# XHSC_HC32L021 register map
Vendor: XHSC Co.Ltd; Series: ARMCM0+; File version: 1.0
CPU: CM0+ r0p1, little endian, no MPU, no FPU, 2 interrupt priority bits
Registers are 32-bit, read-write, reset 0x0 unless marked. A register's access mark holds for its fields unless they carry their own. Offsets are from the block's base; [hi:lo] are bit positions; 'fields as' and 'values as' point back to an identical list.

## IWDT
Base 0x40001000
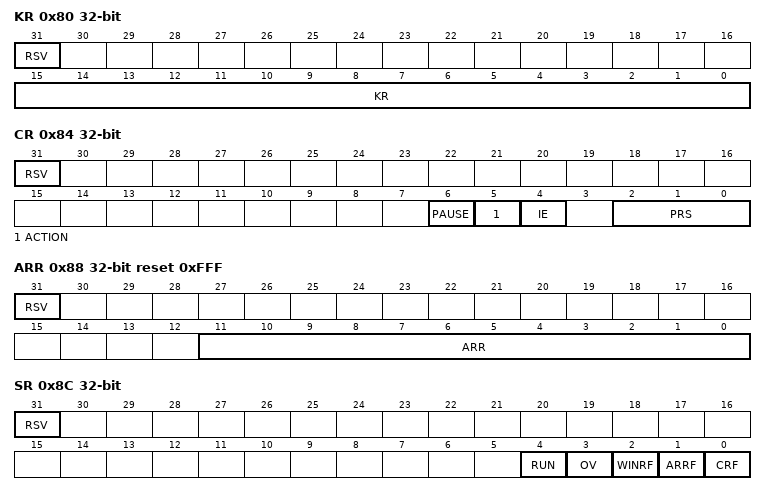
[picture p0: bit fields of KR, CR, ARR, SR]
0x80 KR wo (reset mask 0xFFFF)
  [31] RSV, [15:0] KR
0x84 CR (reset mask 0x77)
  [31] RSV, [6] PAUSE, [5] ACTION, [4] IE, [2:0] PRS
0x88 ARR reset 0xFFF (reset mask 0xFFF)
  [31] RSV, [11:0] ARR
0x8C SR (reset mask 0x1F)
  [31] RSV ro, [4] RUN ro, [3] OV ro, [2] WINRF ro, [1] ARRF ro, [0] CRF ro
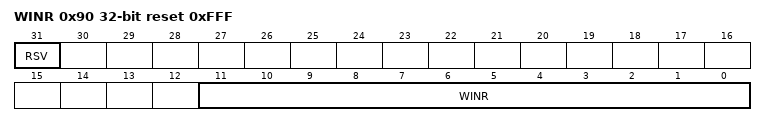
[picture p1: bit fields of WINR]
0x90 WINR reset 0xFFF (reset mask 0xFFF)
  [31] RSV, [11:0] WINR

## LPUART0 — desc LPUART
Base 0x40000000
Same registers: LPUART1 0x40008000
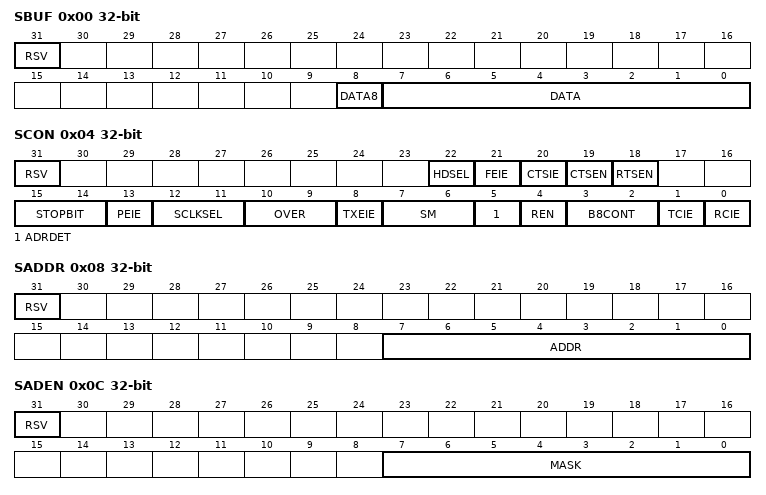
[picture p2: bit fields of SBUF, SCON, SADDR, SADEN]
0x00 SBUF (reset mask 0x1FF)
  [31] RSV, [8] DATA8, [7:0] DATA
0x04 SCON (reset mask 0x7FFFFF)
  [31] RSV, [22] HDSEL, [21] FEIE, [20] CTSIE, [19] CTSEN, [18] RTSEN, [15:14] STOPBIT, [13] PEIE, [12:11] SCLKSEL, [10:9] OVER, [8] TXEIE, [7:6] SM, [5] ADRDET, [4] REN, [3:2] B8CONT, [1] TCIE, [0] RCIE
0x08 SADDR (reset mask 0xFF)
  [31] RSV, [7:0] ADDR
0x0C SADEN (reset mask 0xFF)
  [31] RSV, [7:0] MASK
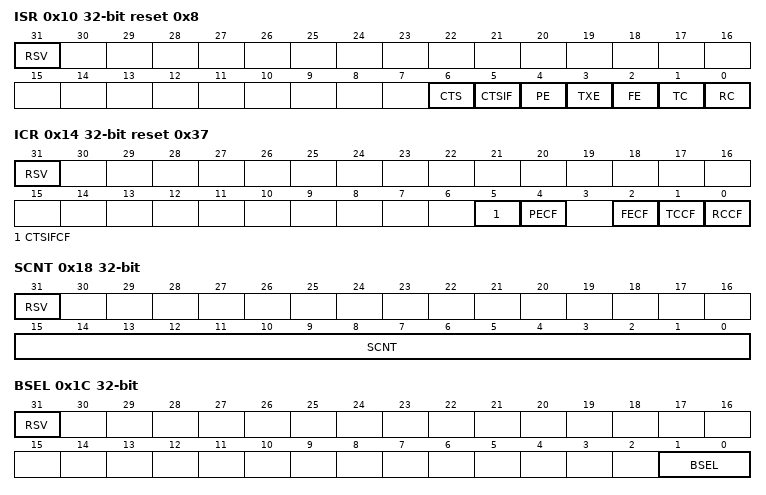
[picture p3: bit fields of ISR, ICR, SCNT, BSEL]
0x10 ISR ro reset 0x8 (reset mask 0x7F)
  [31] RSV rw, [6] CTS, [5] CTSIF, [4] PE, [3] TXE, [2] FE, [1] TC, [0] RC
0x14 ICR wo reset 0x37 (reset mask 0x37)
  [31] RSV rw, [5] CTSIFCF, [4] PECF, [2] FECF, [1] TCCF, [0] RCCF
0x18 SCNT (reset mask 0xFFFF)
  [31] RSV, [15:0] SCNT
0x1C BSEL (reset mask 0x3)
  [31] RSV, [1:0] BSEL
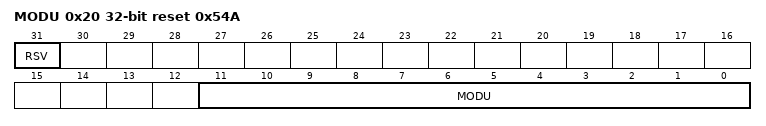
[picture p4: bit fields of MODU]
0x20 MODU reset 0x54A (reset mask 0xFFF)
  [31] RSV, [11:0] MODU

## LVD
Base 0x40002C00
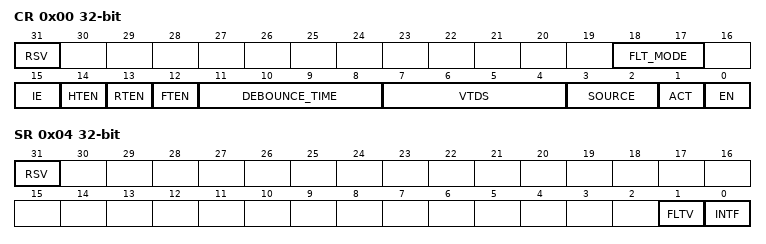
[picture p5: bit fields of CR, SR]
0x00 CR (reset mask 0x6FFFF)
  [31] RSV, [18:17] FLT_MODE, [15] IE, [14] HTEN, [13] RTEN, [12] FTEN, [11:8] DEBOUNCE_TIME, [7:4] VTDS, [3:2] SOURCE, [1] ACT, [0] EN
0x04 SR (reset mask 0x3)
  [31] RSV, [1] FLTV ro, [0] INTF

## RTC
Base 0x40001400
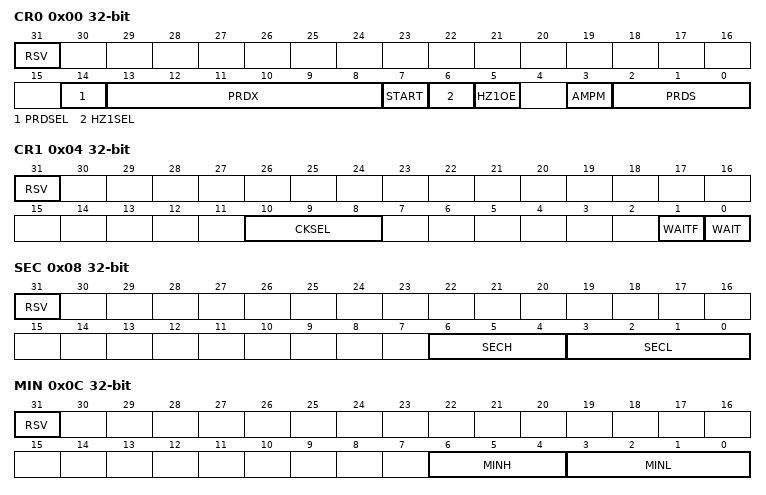
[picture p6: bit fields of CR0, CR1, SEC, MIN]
0x00 CR0 (reset mask 0xFFEF)
  [31] RSV, [14] PRDSEL, [13:8] PRDX, [7] START, [6] HZ1SEL, [5] HZ1OE, [3] AMPM, [2:0] PRDS
0x04 CR1 (reset mask 0x303)
  [31] RSV, [10:8] CKSEL, [1] WAITF, [0] WAIT
0x08 SEC (reset mask 0x7F)
  [31] RSV, [6:4] SECH, [3:0] SECL
0x0C MIN (reset mask 0x7F)
  [31] RSV, [6:4] MINH, [3:0] MINL
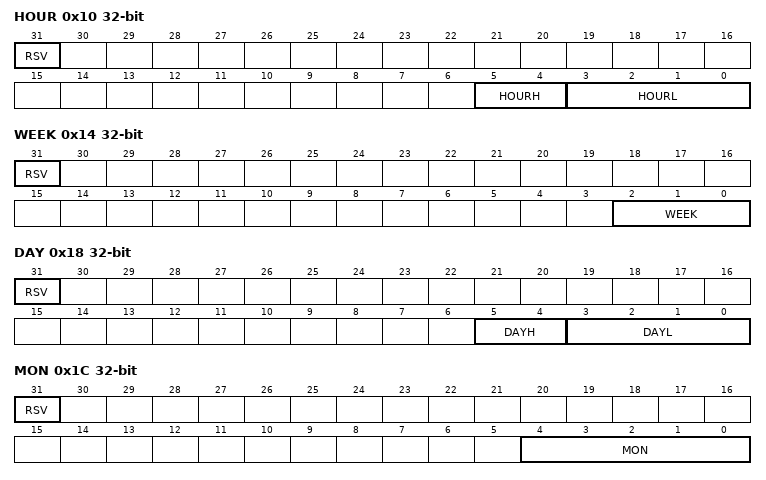
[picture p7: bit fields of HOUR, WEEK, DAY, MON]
0x10 HOUR (reset mask 0x3F)
  [31] RSV, [5:4] HOURH, [3:0] HOURL
0x14 WEEK (reset mask 0x7)
  [31] RSV, [2:0] WEEK
0x18 DAY (reset mask 0x3F)
  [31] RSV, [5:4] DAYH, [3:0] DAYL
0x1C MON (reset mask 0x1F)
  [31] RSV, [4:0] MON
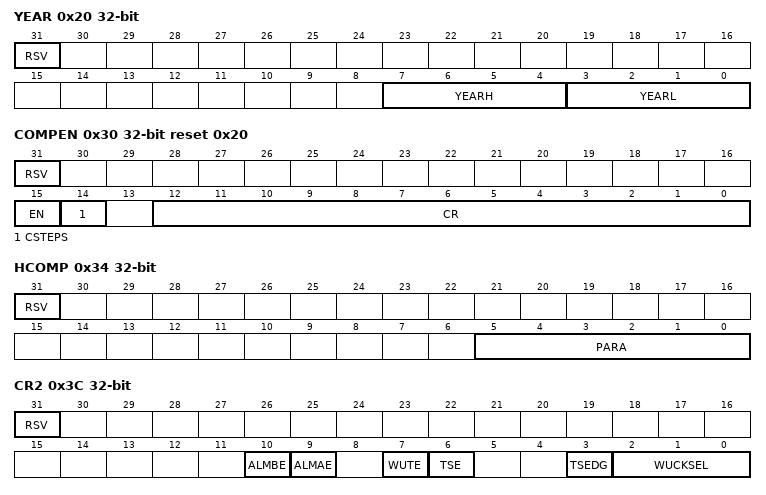
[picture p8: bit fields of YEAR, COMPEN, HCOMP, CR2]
0x20 YEAR (reset mask 0xFF)
  [31] RSV, [7:4] YEARH, [3:0] YEARL
0x30 COMPEN reset 0x20 (reset mask 0x18FF)
  [31] RSV, [15] EN, [14] CSTEPS, [12:0] CR
0x34 HCOMP (reset mask 0x3F)
  [31] RSV, [5:0] PARA
0x3C CR2 (reset mask 0x6FF)
  [31] RSV, [10] ALMBE, [9] ALMAE, [7] WUTE, [6] TSE, [3] TSEDG, [2:0] WUCKSEL
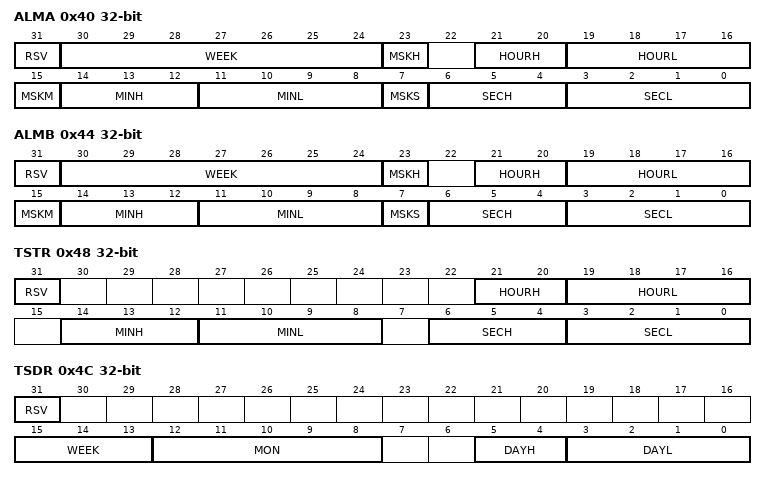
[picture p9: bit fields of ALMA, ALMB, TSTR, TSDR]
0x40 ALMA (reset mask 0x7FBFFFFF)
  [31] RSV, [30:24] WEEK, [23] MSKH, [21:20] HOURH, [19:16] HOURL, [15] MSKM, [14:12] MINH, [11:8] MINL, [7] MSKS, [6:4] SECH, [3:0] SECL
0x44 ALMB (reset mask 0x7FBFFFFF)
  fields as ALMA
0x48 TSTR ro (reset mask 0x3F7F7F)
  [31] RSV, [21:20] HOURH, [19:16] HOURL, [14:12] MINH, [11:8] MINL, [6:4] SECH, [3:0] SECL
0x4C TSDR ro (reset mask 0xFF3F)
  [31] RSV, [15:13] WEEK, [12:8] MON, [5:4] DAYH, [3:0] DAYL
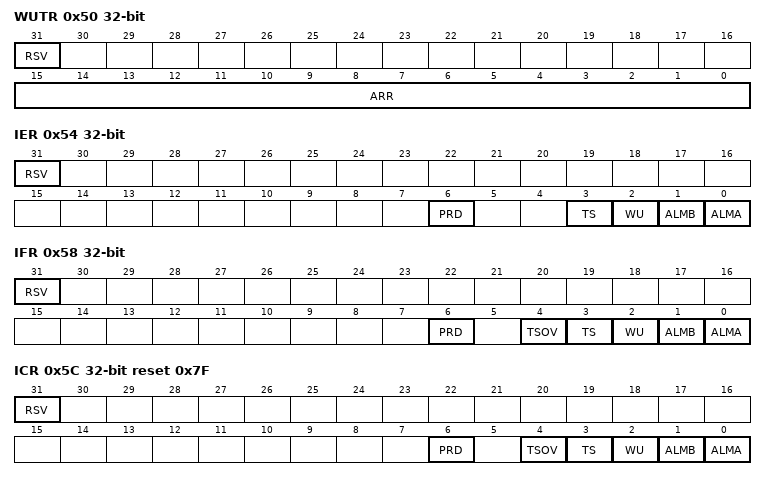
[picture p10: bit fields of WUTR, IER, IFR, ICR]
0x50 WUTR (reset mask 0xFFFF)
  [31] RSV, [15:0] ARR
0x54 IER (reset mask 0x5F)
  [31] RSV, [6] PRD, [3] TS, [2] WU, [1] ALMB, [0] ALMA
0x58 IFR ro (reset mask 0x5F)
  [31] RSV, [6] PRD, [4] TSOV, [3] TS, [2] WU, [1] ALMB, [0] ALMA
0x5C ICR reset 0x7F (reset mask 0x5F)
  [31] RSV, [6] PRD, [4] TSOV, [3] TS, [2] WU, [1] ALMB, [0] ALMA
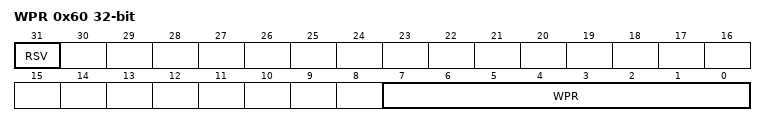
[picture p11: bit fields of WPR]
0x60 WPR (reset mask 0xFF)
  [31] RSV, [7:0] WPR

## SPI
Base 0x40000800
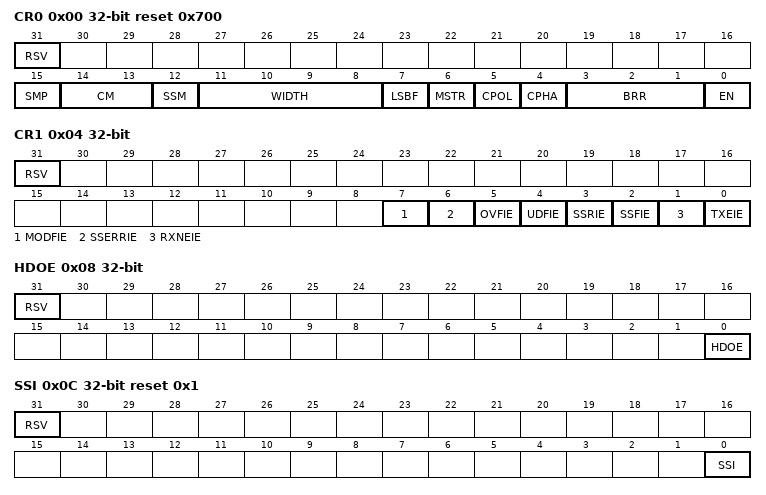
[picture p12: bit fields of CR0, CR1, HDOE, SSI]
0x00 CR0 reset 0x700 (reset mask 0xFFFF)
  [31] RSV, [15] SMP, [14:13] CM, [12] SSM, [11:8] WIDTH, [7] LSBF, [6] MSTR, [5] CPOL, [4] CPHA, [3:1] BRR, [0] EN
0x04 CR1 (reset mask 0xFF)
  [31] RSV, [7] MODFIE, [6] SSERRIE, [5] OVFIE, [4] UDFIE, [3] SSRIE, [2] SSFIE, [1] RXNEIE, [0] TXEIE
0x08 HDOE (reset mask 0x1)
  [31] RSV, [0] HDOE
0x0C SSI reset 0x1 (reset mask 0x1)
  [31] RSV, [0] SSI
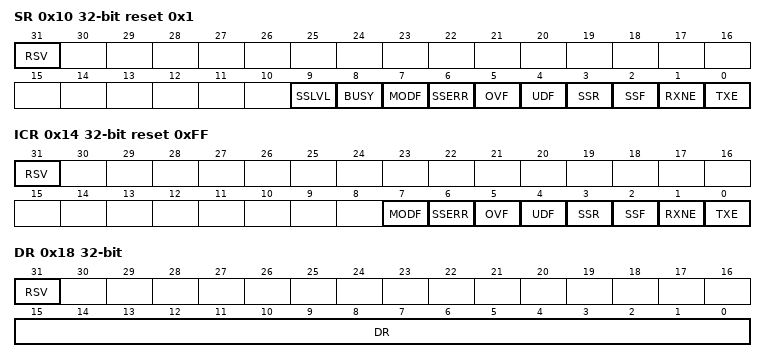
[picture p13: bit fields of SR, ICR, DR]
0x10 SR ro reset 0x1 (reset mask 0x3FF)
  [31] RSV, [9] SSLVL, [8] BUSY, [7] MODF, [6] SSERR, [5] OVF, [4] UDF, [3] SSR, [2] SSF, [1] RXNE, [0] TXE
0x14 ICR wo reset 0xFF (reset mask 0xFF)
  [31] RSV, [7] MODF, [6] SSERR, [5] OVF, [4] UDF, [3] SSR, [2] SSF, [1] RXNE, [0] TXE
0x18 DR (reset mask 0xFF)
  [31] RSV, [15:0] DR

## SYSCTRL
Base 0x40021800
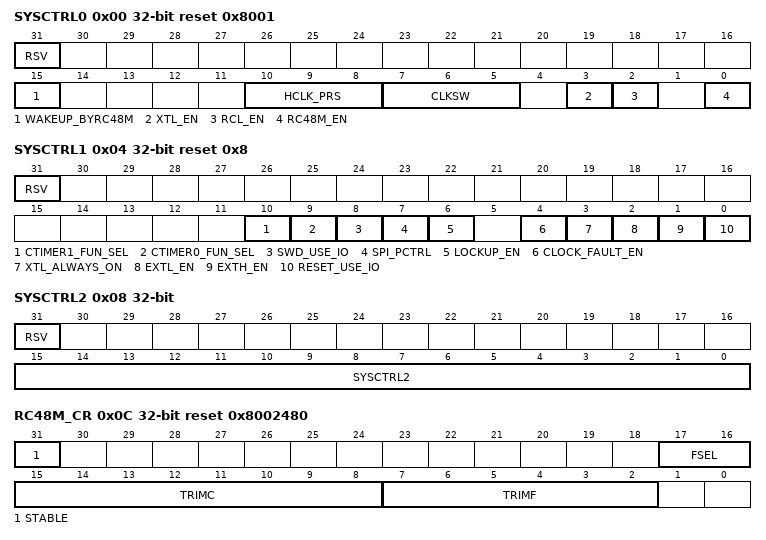
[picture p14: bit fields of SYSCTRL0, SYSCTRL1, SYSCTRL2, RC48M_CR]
0x00 SYSCTRL0 reset 0x8001 (reset mask 0x876D)
  [31] RSV, [15] WAKEUP_BYRC48M, [10:8] HCLK_PRS, [7:5] CLKSW, [3] XTL_EN, [2] RCL_EN, [0] RC48M_EN
0x04 SYSCTRL1 reset 0x8 (reset mask 0x7DF)
  [31] RSV, [10] CTIMER1_FUN_SEL, [9] CTIMER0_FUN_SEL, [8] SWD_USE_IO, [7] SPI_PCTRL, [6] LOCKUP_EN, [4] CLOCK_FAULT_EN, [3] XTL_ALWAYS_ON, [2] EXTL_EN, [1] EXTH_EN, [0] RESET_USE_IO
0x08 SYSCTRL2 (reset mask 0xFFFF)
  [31] RSV, [15:0] SYSCTRL2 wo
0x0C RC48M_CR reset 0x8002480 (reset mask 0x8003FFF3)
  [31] STABLE ro, [17:16] FSEL, [15:8] TRIMC, [7:2] TRIMF
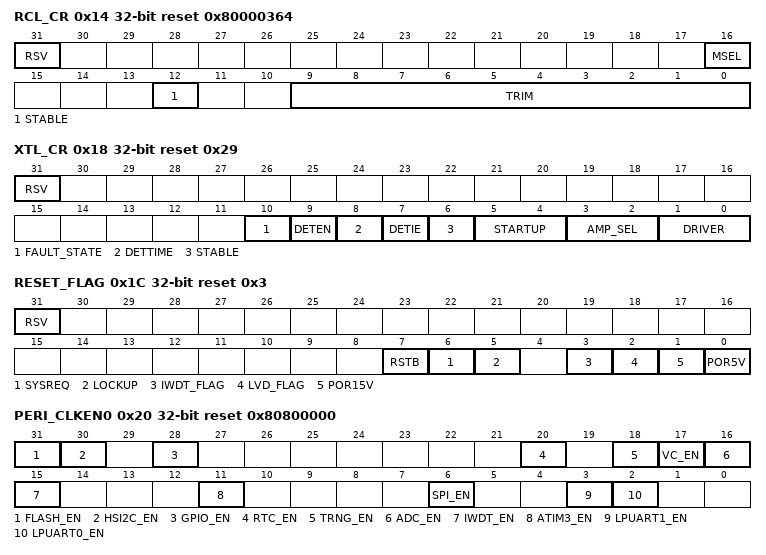
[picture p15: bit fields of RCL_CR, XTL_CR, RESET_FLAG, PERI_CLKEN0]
0x14 RCL_CR reset 0x80000364 (reset mask 0x113FF)
  [31] RSV, [16] MSEL, [12] STABLE ro, [9:0] TRIM
0x18 XTL_CR reset 0x29 (reset mask 0x7FF)
  [31] RSV, [10] FAULT_STATE, [9] DETEN, [8] DETTIME, [7] DETIE, [6] STABLE ro, [5:4] STARTUP, [3:2] AMP_SEL, [1:0] DRIVER
0x1C RESET_FLAG reset 0x3 (reset mask 0x27F)
  [31] RSV, [7] RSTB, [6] SYSREQ, [5] LOCKUP, [3] IWDT_FLAG, [2] LVD_FLAG, [1] POR15V, [0] POR5V
0x20 PERI_CLKEN0 reset 0x80800000
  [31] FLASH_EN, [30] HSI2C_EN, [28] GPIO_EN, [20] RTC_EN, [18] TRNG_EN, [17] VC_EN, [16] ADC_EN, [15] IWDT_EN, [11] ATIM3_EN, [6] SPI_EN, [3] LPUART1_EN, [2] LPUART0_EN
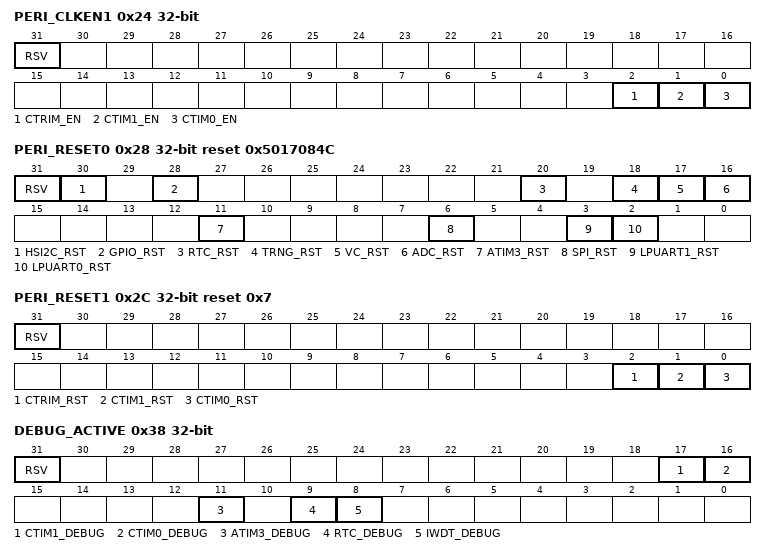
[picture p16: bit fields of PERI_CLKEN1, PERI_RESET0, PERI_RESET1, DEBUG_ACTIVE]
0x24 PERI_CLKEN1 (reset mask 0x7)
  [31] RSV, [2] CTRIM_EN, [1] CTIM1_EN, [0] CTIM0_EN
0x28 PERI_RESET0 reset 0x5017084C (reset mask 0x5017084A)
  [31] RSV, [30] HSI2C_RST, [28] GPIO_RST, [20] RTC_RST, [18] TRNG_RST, [17] VC_RST, [16] ADC_RST, [11] ATIM3_RST, [6] SPI_RST, [3] LPUART1_RST, [2] LPUART0_RST
0x2C PERI_RESET1 reset 0x7 (reset mask 0x7)
  [31] RSV, [2] CTRIM_RST, [1] CTIM1_RST, [0] CTIM0_RST
0x38 DEBUG_ACTIVE (reset mask 0x30B00)
  [31] RSV, [17] CTIM1_DEBUG, [16] CTIM0_DEBUG, [11] ATIM3_DEBUG, [9] RTC_DEBUG, [8] IWDT_DEBUG

## TRNG
Base 0x40008C00
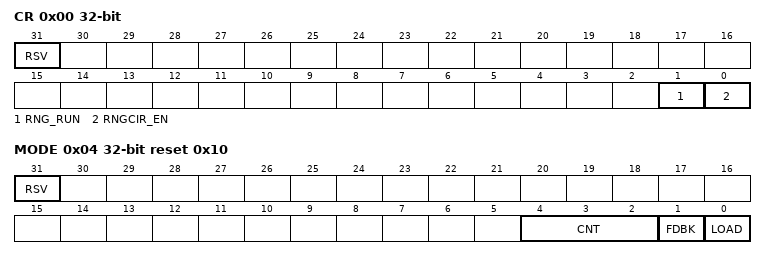
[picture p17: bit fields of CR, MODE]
0x00 CR (reset mask 0x3)
  [31] RSV, [1] RNG_RUN, [0] RNGCIR_EN
0x04 MODE reset 0x10 (reset mask 0x1F)
  [31] RSV, [4:2] CNT, [1] FDBK, [0] LOAD
0x0C DATA0 ro
0x10 DATA1 ro

## VC
Base 0x40002800
0x00 VC0_CR0 reset 0x20 (reset mask 0xF7F)
  [31] RSV, [11:10] HYS, [9:8] BIAS, [6] DIV_EN, [5:0] DIV
0x04 VC0_CR1 reset 0xFF (reset mask 0xFFFFF)
  [31] RSV, [19:18] FLT_MODE, [17] FLTCLK, [16] EN, [15] IE, [14] LEVEL, [13] RISING, [12] FALLING, [11:8] FLTTIME, [7:4] NSEL, [3:0] PSEL
0x08 VC0_CR2 (reset mask 0x771)
  [31] RSV, [10:8] BLANK, [6] WINDOW, [5] ATIMBK, [4] ATIM3CLR, [0] POL
0x0C VC0_SR (reset mask 0x3)
  [31] RSV, [1] FLTV ro, [0] INTF
0x10 VC1_CR0 reset 0x20 (reset mask 0xF7F)
  [31] RSV, [11:10] HYS, [9:8] BIAS, [6] DIV_EN, [5:0] DIV
0x14 VC1_CR1 reset 0xFF (reset mask 0xFFFFF)
  fields as VC0_CR1
0x18 VC1_CR2 (reset mask 0x771)
  fields as VC0_CR2
0x1C VC1_SR (reset mask 0x3)
  [31] RSV, [1] FLTV ro, [0] INTF
0x20 VC_TRIM (reset mask 0xFF)
  [31] RSV, [7:4] TRIM1, [3:0] TRIM0
